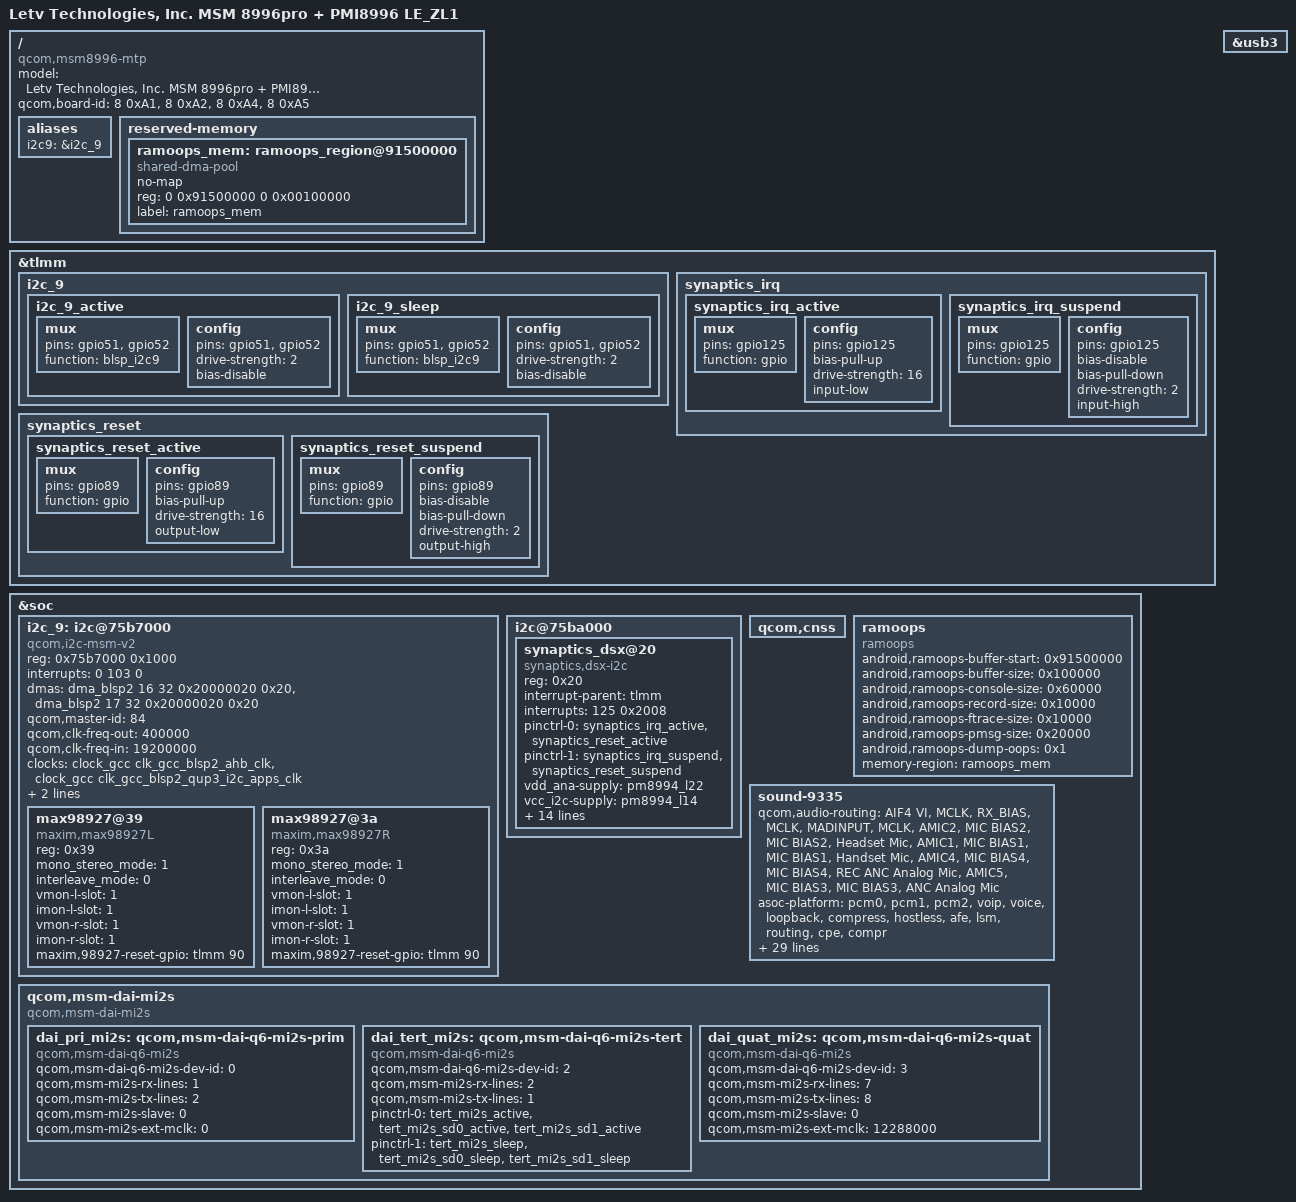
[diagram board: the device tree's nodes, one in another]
/*
 * Copyright (C) 2018, Comma.ai, Inc.
 *
 * This program is free software; you can redistribute it and/or modify
 * it under the terms of the GNU General Public License version 2 and
 * only version 2 as published by the Free Software Foundation.
 *
 * This program is distributed in the hope that it will be useful,
 * but WITHOUT ANY WARRANTY; without even the implied warranty of
 * MERCHANTABILITY or FITNESS FOR A PARTICULAR PURPOSE.  See the
 * GNU General Public License for more details.
 */

/dts-v1/;

#include "msm8996pro.dtsi"
#include "msm-pmi8996.dtsi"
#include "msm8996-mtp.dtsi"
#include "dsi-panel-s6d6fa1-1080p-video.dtsi"

/ {
	model = "Letv Technologies, Inc. MSM 8996pro + PMI8996 LE_ZL1";
	compatible = "qcom,msm8996-mtp", "qcom,msm8996", "qcom,mtp";
	qcom,board-id = <8 0xA1>, <8 0xA2>, <8 0xA4>, <8 0xA5>;

	aliases {
		i2c9 = &i2c_9;
	};

	reserved-memory {
		ramoops_mem: ramoops_region@91500000 {
			compatible = "shared-dma-pool";
			no-map;
			reg = <0 0x91500000 0 0x00100000>;
			label = "ramoops_mem";
		};
	};
};

&tlmm {
	i2c_9 {
		i2c_9_active: i2c_9_active {
			mux {
				pins = "gpio51", "gpio52";
				function = "blsp_i2c9";
			};

			config {
				pins = "gpio51", "gpio52";
				drive-strength = <2>;
				bias-disable;
			};
		};

		i2c_9_sleep: i2c_9_sleep {
			mux {
				pins = "gpio51", "gpio52";
				function = "blsp_i2c9";
			};

			config {
				pins = "gpio51", "gpio52";
				drive-strength = <2>;
				bias-disable;
			};
		};
	};

	synaptics_irq {
		synaptics_irq_active: synaptics_irq_active {
			mux {
				pins = "gpio125";
				function = "gpio";
			};
			config {
				pins = "gpio125";
				bias-pull-up;
				drive-strength = <16>;
				input-low;
			};
		};

		synaptics_irq_suspend: synaptics_irq_suspend {
			mux {
				pins = "gpio125";
				function = "gpio";
			};
			config {
				pins = "gpio125";
				bias-disable;
				bias-pull-down;
				drive-strength = <2>;
				input-high;
			};
		};
	};

	synaptics_reset {
		synaptics_reset_active: synaptics_reset_active {
			mux {
				pins = "gpio89";
				function = "gpio";
			};
			config {
				pins = "gpio89";
				bias-pull-up;
				drive-strength = <16>;
				output-low;
			};
		};

		synaptics_reset_suspend: synaptics_reset_suspend {
			mux {
				pins = "gpio89";
				function = "gpio";
			};
			config {
				pins = "gpio89";
				bias-disable;
				bias-pull-down;
				drive-strength = <2>;
				output-high;
			};
		};
	};
};

&soc {
	i2c_9: i2c@75b7000 {
		compatible = "qcom,i2c-msm-v2";
		#address-cells = <1>;
		#size-cells = <0>;
		reg-names = "qup_phys_addr";
		reg = <0x75b7000 0x1000>;
		interrupt-names = "qup_irq";
		interrupts = <0 103 0>;
		dmas = <&dma_blsp2 16 32 0x20000020 0x20>,
			<&dma_blsp2 17 32 0x20000020 0x20>;
		dma-names = "tx", "rx";
		qcom,master-id = <84>;
		qcom,clk-freq-out = <400000>;
		qcom,clk-freq-in  = <19200000>;
		clock-names = "iface_clk", "core_clk";
		clocks = <&clock_gcc clk_gcc_blsp2_ahb_clk>,
			 <&clock_gcc clk_gcc_blsp2_qup3_i2c_apps_clk>;
		pinctrl-names = "i2c_active", "i2c_sleep";
		pinctrl-0 = <&i2c_9_active>;
		pinctrl-1 = <&i2c_9_sleep>;

		max98927@39 {
			compatible = "maxim,max98927L";
			reg = <0x39>;
			mono_stereo_mode = <1>;
			interleave_mode = <0>;
			vmon-l-slot = <1>;
			imon-l-slot = <1>;
			vmon-r-slot = <1>;
			imon-r-slot = <1>;
			maxim,98927-reset-gpio = <&tlmm 90 0>;
		};

		max98927@3a {
			compatible = "maxim,max98927R";
			reg = <0x3a>;
			mono_stereo_mode = <1>;
			interleave_mode = <0>;
			vmon-l-slot = <1>;
			imon-l-slot = <1>;
			vmon-r-slot = <1>;
			imon-r-slot = <1>;
			maxim,98927-reset-gpio = <&tlmm 90 0>;
		};
	};

	i2c@75ba000 {
		/delete-node/ synaptics@20;

		synaptics_dsx@20 {
			compatible = "synaptics,dsx-i2c";
			reg = <0x20>;
			interrupt-parent = <&tlmm>;
			interrupts = <125 0x2008>;
			pinctrl-names = "pmx_ts_active","pmx_ts_suspend";
			pinctrl-0 = <&synaptics_irq_active &synaptics_reset_active>;
			pinctrl-1 = <&synaptics_irq_suspend &synaptics_reset_suspend>;
			vdd_ana-supply = <&pm8994_l22>;
			vcc_i2c-supply = <&pm8994_l14>;
			synaptics,pwr-reg-name = "vdd_ana";
			synaptics,bus-reg-name = "vcc_i2c";
			synaptics,reset-gpio = <&tlmm 89 0x00>;
			synaptics,irq-gpio = <&tlmm 125 0x2008>;
			synaptics,irq-on-state = <0>;
			synaptics,irq-flags = <0x2008>;
			synaptics,power-delay-ms = <200>;
			synaptics,reset-delay-ms = <200>;
			synaptics,reset-on-state = <0>;
			synaptics,reset-active-ms = <20>;
			synaptics,disable-gpios;
			synaptics,cap-button-codes = <580 172 158>;
			synaptics,driver-line-num = <31>;
			synaptics,sense-line-num = <20>;
		};
	};

	qcom,cnss {
		/delete-property/ qcom,wlan-ramdump-dynamic;
	};

	ramoops {
		compatible = "ramoops";
		status = "ok";
		android,ramoops-buffer-start = <0x91500000>;
		android,ramoops-buffer-size =  <0x100000>;
		android,ramoops-console-size = <0x60000>;
		android,ramoops-record-size = <0x10000>;
		android,ramoops-ftrace-size = <0x10000>;
		android,ramoops-pmsg-size = <0x20000>;
		android,ramoops-dump-oops = <0x1>;
		memory-region = <&ramoops_mem>;
	};

	sound-9335 {
		/delete-property/ qcom,hph-en1-gpio;
		/delete-property/ qcom,hph-en0-gpio;
		/delete-property/ qcom,wsa-devs;
		/delete-property/ qcom,wsa-aux-dev-prefix;

		qcom,audio-routing =
			"AIF4 VI", "MCLK",
			"RX_BIAS", "MCLK",
			"MADINPUT", "MCLK",
			"AMIC2", "MIC BIAS2",
			"MIC BIAS2", "Headset Mic",
			"AMIC1", "MIC BIAS1",
			"MIC BIAS1", "Handset Mic",
			"AMIC4", "MIC BIAS4",
			"MIC BIAS4", "REC ANC Analog Mic",
			"AMIC5", "MIC BIAS3",
			"MIC BIAS3", "ANC Analog Mic";

		asoc-platform = <&pcm0>, <&pcm1>, <&pcm2>, <&voip>, <&voice>,
				<&loopback>, <&compress>, <&hostless>,
				<&afe>, <&lsm>, <&routing>, <&cpe>, <&compr>;
		asoc-platform-names = "msm-pcm-dsp.0", "msm-pcm-dsp.1", "msm-pcm-dsp.2",
				"msm-voip-dsp", "msm-pcm-voice", "msm-pcm-loopback",
				"msm-compress-dsp", "msm-pcm-hostless", "msm-pcm-afe",
				"msm-lsm-client", "msm-pcm-routing", "msm-cpe-lsm",
				"msm-compr-dsp";
		asoc-cpu = <&dai_pri_auxpcm>, <&dai_sec_auxpcm>, <&dai_hdmi>,
				<&dai_pri_mi2s>,
				<&dai_tert_mi2s>, <&dai_quat_mi2s>,
				<&sb_0_rx>, <&sb_0_tx>, <&sb_1_rx>, <&sb_1_tx>,
				<&sb_2_rx>, <&sb_2_tx>, <&sb_3_rx>, <&sb_3_tx>,
				<&sb_4_rx>, <&sb_4_tx>, <&sb_5_tx>, <&afe_pcm_rx>,
				<&afe_pcm_tx>, <&afe_proxy_rx>, <&afe_proxy_tx>,
				<&incall_record_rx>, <&incall_record_tx>,
				<&incall_music_rx>, <&incall_music2_rx>,
				<&sb_5_rx>, <&sb_6_rx>;
		asoc-cpu-names = "msm-dai-q6-auxpcm.1", "msm-dai-q6-auxpcm.2",
				"msm-dai-q6-hdmi.8",
				"msm-dai-q6-mi2s.0",
				"msm-dai-q6-mi2s.2", "msm-dai-q6-mi2s.3",
				"msm-dai-q6-dev.16384", "msm-dai-q6-dev.16385",
				"msm-dai-q6-dev.16386", "msm-dai-q6-dev.16387",
				"msm-dai-q6-dev.16388", "msm-dai-q6-dev.16389",
				"msm-dai-q6-dev.16390", "msm-dai-q6-dev.16391",
				"msm-dai-q6-dev.16392", "msm-dai-q6-dev.16393",
				"msm-dai-q6-dev.16395", "msm-dai-q6-dev.224",
				"msm-dai-q6-dev.225", "msm-dai-q6-dev.241",
				"msm-dai-q6-dev.240", "msm-dai-q6-dev.32771",
				"msm-dai-q6-dev.32772", "msm-dai-q6-dev.32773",
				"msm-dai-q6-dev.32770", "msm-dai-q6-dev.16394",
				"msm-dai-q6-dev.16396";
	};

	qcom,msm-dai-mi2s {
		compatible = "qcom,msm-dai-mi2s";
		dai_pri_mi2s: qcom,msm-dai-q6-mi2s-prim {
			compatible = "qcom,msm-dai-q6-mi2s";
			qcom,msm-dai-q6-mi2s-dev-id = <0>;
			qcom,msm-mi2s-rx-lines = <1>;
			qcom,msm-mi2s-tx-lines = <2>;
			qcom,msm-mi2s-slave = <0>;
			qcom,msm-mi2s-ext-mclk = <0>;
		};
	};

	qcom,msm-dai-mi2s {
		compatible = "qcom,msm-dai-mi2s";
		dai_tert_mi2s: qcom,msm-dai-q6-mi2s-tert {
			compatible = "qcom,msm-dai-q6-mi2s";
			qcom,msm-dai-q6-mi2s-dev-id = <2>;
			qcom,msm-mi2s-rx-lines = <2>;
			qcom,msm-mi2s-tx-lines = <1>;
			pinctrl-names = "default", "sleep";
			pinctrl-0 = <&tert_mi2s_active &tert_mi2s_sd0_active &tert_mi2s_sd1_active>;
			pinctrl-1 = <&tert_mi2s_sleep &tert_mi2s_sd0_sleep &tert_mi2s_sd1_sleep>;
		};
	};

	qcom,msm-dai-mi2s {
		compatible = "qcom,msm-dai-mi2s";
		dai_quat_mi2s: qcom,msm-dai-q6-mi2s-quat {
			compatible = "qcom,msm-dai-q6-mi2s";
			qcom,msm-dai-q6-mi2s-dev-id = <3>;
			qcom,msm-mi2s-rx-lines = <7>;
			qcom,msm-mi2s-tx-lines = <8>;
			qcom,msm-mi2s-slave = <0>;
			qcom,msm-mi2s-ext-mclk = <12288000>;
		};
	};
};

&usb3 {
	/delete-property/ vbus_dwc3-supply;
};
